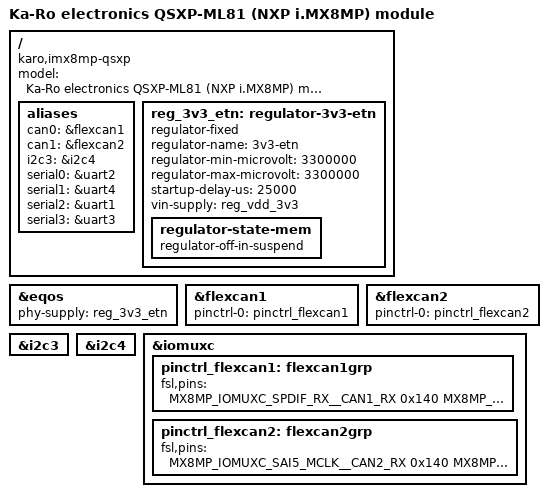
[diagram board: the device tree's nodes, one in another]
// SPDX-License-Identifier: (GPL-2.0 OR MIT)
/*
 * Copyright (C) 2020 Lothar Waßmann <LW@KARO-electronics.de>
 *
 */

/dts-v1/;

#include "imx8mp-karo.dtsi"

/ {
	model = "Ka-Ro electronics QSXP-ML81 (NXP i.MX8MP) module";
	compatible = "karo,imx8mp-qsxp", "fsl,imx8mp";

	aliases {
		can0 = &flexcan1;
		can1 = &flexcan2;
		/delete-property/ ethernet1;
		i2c3 = &i2c4;
		serial0 = &uart2;
		serial1 = &uart4;
		serial2 = &uart1;
		serial3 = &uart3;
	};

	reg_3v3_etn: regulator-3v3-etn {
		compatible = "regulator-fixed";
		regulator-name = "3v3-etn";
		regulator-min-microvolt = <3300000>;
		regulator-max-microvolt = <3300000>;
		startup-delay-us = <25000>;
		vin-supply = <&reg_vdd_3v3>;

		regulator-state-mem {
			regulator-off-in-suspend;
		};
	};
};

&eqos {
	phy-supply = <&reg_3v3_etn>;
};

&flexcan1 {
	pinctrl-names = "default";
	pinctrl-0 = <&pinctrl_flexcan1>;
};

&flexcan2 {
	pinctrl-names = "default";
	pinctrl-0 = <&pinctrl_flexcan2>;
};

&i2c3 {
	status = "okay";
};

&i2c4 {
	status = "okay";
};

&iomuxc {
	pinctrl_flexcan1: flexcan1grp {
		fsl,pins = <
			 MX8MP_IOMUXC_SPDIF_RX__CAN1_RX		0x140
			 MX8MP_IOMUXC_SPDIF_TX__CAN1_TX		0x140
		>;
	};

	pinctrl_flexcan2: flexcan2grp {
		fsl,pins = <
			 MX8MP_IOMUXC_SAI5_MCLK__CAN2_RX	0x140
			 MX8MP_IOMUXC_SAI5_RXD3__CAN2_TX	0x140
		>;
	};
};
